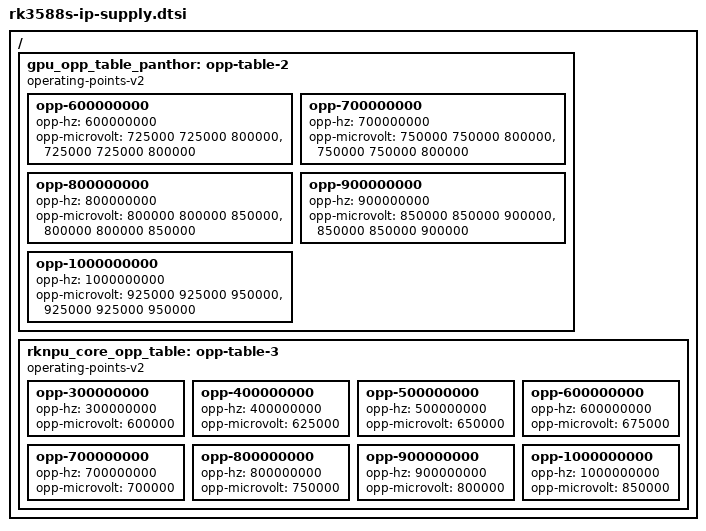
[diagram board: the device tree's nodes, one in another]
// SPDX-License-Identifier: (GPL-2.0+ OR MIT)

/ {
	gpu_opp_table_panthor: opp-table-2 {
		compatible = "operating-points-v2";

		opp-600000000 {
			opp-hz = /bits/ 64 <600000000>;
			opp-microvolt = <725000 725000 800000>,
					<725000 725000 800000>;
		};

		opp-700000000 {
			opp-hz = /bits/ 64 <700000000>;
			opp-microvolt = <750000 750000 800000>,
					<750000 750000 800000>;
		};

		opp-800000000 {
			opp-hz = /bits/ 64 <800000000>;
			opp-microvolt = <800000 800000 850000>,
					<800000 800000 850000>;
		};

		opp-900000000 {
			opp-hz = /bits/ 64 <900000000>;
			opp-microvolt = <850000 850000 900000>,
					<850000 850000 900000>;
		};

		opp-1000000000 {
			opp-hz = /bits/ 64 <1000000000>;
			opp-microvolt = <925000 925000 950000>,
					<925000 925000 950000>;
		};
	};

	rknpu_core_opp_table: opp-table-3 {
		compatible = "operating-points-v2";

		opp-300000000 {
			opp-hz = /bits/ 64 <300000000>;
			opp-microvolt = <600000>;
		};

		opp-400000000 {
			opp-hz = /bits/ 64 <400000000>;
			opp-microvolt = <625000>;
		};

		opp-500000000 {
			opp-hz = /bits/ 64 <500000000>;
			opp-microvolt = <650000>;
		};

		opp-600000000 {
			opp-hz = /bits/ 64 <600000000>;
			opp-microvolt = <675000>;
		};

		opp-700000000 {
			opp-hz = /bits/ 64 <700000000>;
			opp-microvolt = <700000>;
		};

		opp-800000000 {
			opp-hz = /bits/ 64 <800000000>;
			opp-microvolt = <750000>;
		};

		opp-900000000 {
			opp-hz = /bits/ 64 <900000000>;
			opp-microvolt = <800000>;
		};

		opp-1000000000 {
			opp-hz = /bits/ 64 <1000000000>;
			opp-microvolt = <850000>;
		};
	};
};
